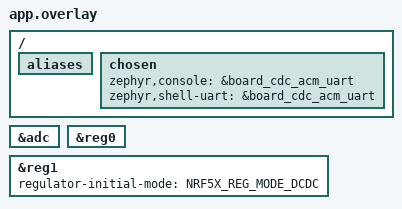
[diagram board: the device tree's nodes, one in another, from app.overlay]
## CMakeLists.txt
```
cmake_minimum_required(VERSION 3.20.0)
find_package(Zephyr REQUIRED HINTS $ENV{ZEPHYR_BASE})

project(firmware)

target_sources(app PRIVATE
    src/main.c
    src/led.c
    src/ble.c
    src/ble_service.c
    src/usb_console.c
    src/temperature.c
    src/console_commands.c
    src/dfu.c
    src/motor.c
    src/sensor.c
)
```

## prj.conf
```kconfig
CONFIG_BT=y
CONFIG_BT_PERIPHERAL=y
CONFIG_BT_DEVICE_NAME="ProMicro_BLE"
CONFIG_BT_DEVICE_APPEARANCE=833
CONFIG_BT_L2CAP_TX_MTU=498
CONFIG_BT_BUF_ACL_RX_SIZE=502
CONFIG_BT_BUF_ACL_TX_SIZE=502
CONFIG_BT_CTLR_DATA_LENGTH_MAX=251

CONFIG_GPIO=y
CONFIG_ADC=y

# USB CDC ACM console / shell
CONFIG_USB_DEVICE_STACK=y
CONFIG_USB_CDC_ACM=y
CONFIG_USB_DEVICE_INITIALIZE_AT_BOOT=n
CONFIG_USB_DEVICE_VID=0x2FE3
CONFIG_USB_DEVICE_PID=0x0100
CONFIG_SERIAL=y
CONFIG_CONSOLE=y
CONFIG_UART_CONSOLE=y
CONFIG_UART_LINE_CTRL=y
CONFIG_UART_INTERRUPT_DRIVEN=y

# Shell
CONFIG_SHELL=y
CONFIG_SHELL_BACKEND_SERIAL=y
CONFIG_SHELL_LOG_BACKEND=n
CONFIG_SHELL_PROMPT_UART="yayo:~$ "
CONFIG_MCUMGR_TRANSPORT_SHELL=y

# MCUboot / MCUmgr
CONFIG_BOOTLOADER_MCUBOOT=y
CONFIG_IMG_MANAGER=y
CONFIG_MCUMGR=y
CONFIG_MCUMGR_GRP_IMG=y
CONFIG_MCUMGR_GRP_OS=y
CONFIG_MCUMGR_GRP_OS_MCUMGR_PARAMS=y
CONFIG_MCUMGR_TRANSPORT_BT=y
CONFIG_MCUMGR_TRANSPORT_BT_CONN_PARAM_CONTROL=y
CONFIG_MCUMGR_TRANSPORT_BT_PERM_RW=y
CONFIG_MCUMGR_TRANSPORT_BT_REASSEMBLY=y
CONFIG_MCUMGR_TRANSPORT_NETBUF_SIZE=2475
CONFIG_MCUMGR_TRANSPORT_WORKQUEUE_STACK_SIZE=4608
CONFIG_NET_BUF=y
CONFIG_ZCBOR=y
CONFIG_CRC=y
CONFIG_STREAM_FLASH=y
CONFIG_BASE64=y
CONFIG_SYSTEM_WORKQUEUE_STACK_SIZE=4608
CONFIG_MAIN_STACK_SIZE=3072

# Reboot (DFU)
CONFIG_REBOOT=y

# Flash storage
CONFIG_FLASH=y
CONFIG_FLASH_MAP=y
CONFIG_NVS=y

# Temperature Sensor
CONFIG_SENSOR=y
CONFIG_TEMP_NRF5=y
```

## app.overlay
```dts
#include <zephyr/dt-bindings/pinctrl/nrf-pinctrl.h>

/ {
    aliases {
    };

    chosen {
        zephyr,console = &board_cdc_acm_uart;
        zephyr,shell-uart = &board_cdc_acm_uart;
    };
};

&adc {
    status = "okay";
};

&reg0 {
    status = "okay";
};

&reg1 {
    regulator-initial-mode = <NRF5X_REG_MODE_DCDC>;
};
```

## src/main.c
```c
#include <zephyr/kernel.h>
#include <zephyr/dfu/mcuboot.h>
#include <zephyr/sys/printk.h>

#include "usb_console.h"
#include "led.h"
#include "ble.h"
#include "temperature.h"
#include "motor.h"
#include "sensor.h"

static void confirm_running_image(void)
{
	if (boot_is_img_confirmed()) {
		return;
	}

	int err = boot_write_img_confirmed();

	if (err) {
		printk("Failed to confirm MCUboot image (err %d)\n", err);
	} else {
		printk("MCUboot image confirmed\n");
	}
}

int main(void)
{
	usb_console_init();
	confirm_running_image();

	printk("\n=== Zephyr BLE Peripheral Starting ===\n");

	if (led_init() < 0) {
		return 0;
	}

	if (ble_init() < 0) {
		return 0;
	}

	if (temperature_init() < 0) {
		return 0;
	}

	sensor_init();

	int32_t hall1 = 0, hall2 = 0;
	struct sensor_battery_status battery = { 0 };
	int battery_notify_divider = 0;

	while (1) {
		temperature_read();
		sensor_read_hall(&hall1, &hall2);
		sensor_calibration_update(hall1, hall2);
		if (sensor_should_trigger_left_click(hall1)) {
			mouse_left_click();
		}
		if (sensor_should_trigger_right_click(hall2)) {
			mouse_right_click();
		}
		mouse_switch_process();
		ble_notify_hall_sensors(hall1, hall2);
		if (++battery_notify_divider >= 20) {
			battery_notify_divider = 0;
			sensor_read_battery(&battery);
			ble_notify_battery(&battery);
		}

		k_sleep(K_MSEC(50)); // Read sensors every 50ms for smooth UI updates
	}
	return 0;
}
```

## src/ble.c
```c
#include "ble.h"

#include "ble_service.h"

#include <zephyr/bluetooth/bluetooth.h>
#include <zephyr/bluetooth/conn.h>
#include <zephyr/bluetooth/uuid.h>
#include <zephyr/kernel.h>
#include <zephyr/sys/printk.h>

/* Custom Service UUID: 2cfd0a83-f013-4fe2-8dbd-fe3a5f4a64ff */
#define BT_UUID_CUSTOM_SERV_VAL \
    BT_UUID_128_ENCODE(0x2cfd0a83, 0xf013, 0x4fe2, 0x8dbd, 0xfe3a5f4a64ff)

#define DEVICE_NAME CONFIG_BT_DEVICE_NAME
#define DEVICE_NAME_LEN (sizeof(DEVICE_NAME) - 1)

static const struct bt_data ad[] = {
    BT_DATA_BYTES(BT_DATA_FLAGS, (BT_LE_AD_GENERAL | BT_LE_AD_NO_BREDR)),
    BT_DATA_BYTES(BT_DATA_UUID16_ALL, BT_UUID_16_ENCODE(BT_UUID_GATT_VAL)),
    BT_DATA_BYTES(BT_DATA_UUID128_ALL, BT_UUID_CUSTOM_SERV_VAL),
};

static const struct bt_data sd[] = {
    BT_DATA(BT_DATA_NAME_COMPLETE, DEVICE_NAME, DEVICE_NAME_LEN),
};

static struct k_work adv_work;

static void start_advertising(void)
{
    struct bt_le_adv_param adv_param = {
        .id = BT_ID_DEFAULT,
        .sid = 0,
        .secondary_max_skip = 0,
        .options = BT_LE_ADV_OPT_CONN,
        .interval_min = 1600,
        .interval_max = 1632,
        .peer = NULL,
    };

    int err = bt_le_adv_start(&adv_param, ad, ARRAY_SIZE(ad), sd, ARRAY_SIZE(sd));

    if (err) {
        printk("Advertising failed to start (err %d)\n", err);
    } else {
        printk("Advertising successfully started\n");
    }
}

static void adv_work_handler(struct k_work *work)
{
    ARG_UNUSED(work);
    start_advertising();
}

static void connected(struct bt_conn *conn, uint8_t err)
{
    ARG_UNUSED(conn);

    if (err) {
        printk("Connection failed (err 0x%02x)\n", err);
    } else {
        printk("Connected\n");
    }
}

static void disconnected(struct bt_conn *conn, uint8_t reason)
{
    ARG_UNUSED(conn);
    printk("Disconnected (reason 0x%02x)\n", reason);
    k_work_submit(&adv_work);
}

BT_CONN_CB_DEFINE(conn_callbacks) = {
    .connected = connected,
    .disconnected = disconnected,
};

static void bt_ready(int err)
{
    if (err) {
        printk("Bluetooth init failed (err %d)\n", err);
        return;
    }

    printk("Bluetooth initialized\n");
    start_advertising();
}

int ble_notify_hall_sensors(int32_t hall1, int32_t hall2)
{
    return ble_service_notify_hall_sensors(hall1, hall2);
}

int ble_notify_battery(const struct sensor_battery_status *status)
{
    return ble_service_notify_battery(status);
}

int ble_notify_temperature(int32_t temperature)
{
    return ble_service_notify_temperature(temperature);
}

int ble_init(void)
{
    k_work_init(&adv_work, adv_work_handler);

    int err = bt_enable(bt_ready);
    if (err) {
        printk("Bluetooth init failed (err %d)\n", err);
        return err;
    }

    return 0;
}
```

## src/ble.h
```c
#ifndef BLE_H
#define BLE_H

#include <stdint.h>

struct sensor_battery_status;

int ble_init(void);
int ble_notify_temperature(int32_t temperature);
int ble_notify_hall_sensors(int32_t hall1, int32_t hall2);
int ble_notify_battery(const struct sensor_battery_status *status);

#endif
```

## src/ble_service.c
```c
#include "ble_service.h"

#include "dfu.h"
#include "led.h"
#include "motor.h"
#include "sensor.h"

#include <stdbool.h>
#include <zephyr/bluetooth/conn.h>
#include <zephyr/bluetooth/gatt.h>
#include <zephyr/bluetooth/uuid.h>
#include <zephyr/kernel.h>
#include <zephyr/sys/printk.h>

/* Custom Service UUID: 2cfd0a83-f013-4fe2-8dbd-fe3a5f4a64ff */
#define BT_UUID_CUSTOM_SERV_VAL \
    BT_UUID_128_ENCODE(0x2cfd0a83, 0xf013, 0x4fe2, 0x8dbd, 0xfe3a5f4a64ff)
#define BT_UUID_CUSTOM_SERV BT_UUID_DECLARE_128(BT_UUID_CUSTOM_SERV_VAL)

/* Custom Characteristic UUID: 2cfd0a84-f013-4fe2-8dbd-fe3a5f4a64ff */
#define BT_UUID_CUSTOM_CHAR_LED_VAL \
    BT_UUID_128_ENCODE(0x2cfd0a84, 0xf013, 0x4fe2, 0x8dbd, 0xfe3a5f4a64ff)
#define BT_UUID_CUSTOM_CHAR_LED BT_UUID_DECLARE_128(BT_UUID_CUSTOM_CHAR_LED_VAL)

/* Custom Characteristic UUID for Temp: 2cfd0a85-f013-4fe2-8dbd-fe3a5f4a64ff */
#define BT_UUID_CUSTOM_CHAR_TEMP_VAL \
    BT_UUID_128_ENCODE(0x2cfd0a85, 0xf013, 0x4fe2, 0x8dbd, 0xfe3a5f4a64ff)
#define BT_UUID_CUSTOM_CHAR_TEMP BT_UUID_DECLARE_128(BT_UUID_CUSTOM_CHAR_TEMP_VAL)

/* Custom Characteristic UUID for Battery: 2cfd0a8d-f013-4fe2-8dbd-fe3a5f4a64ff */
#define BT_UUID_CUSTOM_CHAR_BATTERY_VAL \
    BT_UUID_128_ENCODE(0x2cfd0a8d, 0xf013, 0x4fe2, 0x8dbd, 0xfe3a5f4a64ff)
#define BT_UUID_CUSTOM_CHAR_BATTERY BT_UUID_DECLARE_128(BT_UUID_CUSTOM_CHAR_BATTERY_VAL)

/* Custom Characteristic UUID for Hall1: 2cfd0a87-f013-4fe2-8dbd-fe3a5f4a64ff */
#define BT_UUID_CUSTOM_CHAR_HALL1_VAL \
    BT_UUID_128_ENCODE(0x2cfd0a87, 0xf013, 0x4fe2, 0x8dbd, 0xfe3a5f4a64ff)
#define BT_UUID_CUSTOM_CHAR_HALL1 BT_UUID_DECLARE_128(BT_UUID_CUSTOM_CHAR_HALL1_VAL)

/* Custom Characteristic UUID for Hall2: 2cfd0a88-f013-4fe2-8dbd-fe3a5f4a64ff */
#define BT_UUID_CUSTOM_CHAR_HALL2_VAL \
    BT_UUID_128_ENCODE(0x2cfd0a88, 0xf013, 0x4fe2, 0x8dbd, 0xfe3a5f4a64ff)
#define BT_UUID_CUSTOM_CHAR_HALL2 BT_UUID_DECLARE_128(BT_UUID_CUSTOM_CHAR_HALL2_VAL)

/* Custom Characteristic UUID for Mouse Switch: 2cfd0a89-f013-4fe2-8dbd-fe3a5f4a64ff */
#define BT_UUID_CUSTOM_CHAR_SWITCH_VAL \
    BT_UUID_128_ENCODE(0x2cfd0a89, 0xf013, 0x4fe2, 0x8dbd, 0xfe3a5f4a64ff)
#define BT_UUID_CUSTOM_CHAR_SWITCH BT_UUID_DECLARE_128(BT_UUID_CUSTOM_CHAR_SWITCH_VAL)

/* Custom Characteristic UUID for Calibration Status: 2cfd0a8a-f013-4fe2-8dbd-fe3a5f4a64ff */
#define BT_UUID_CUSTOM_CHAR_CAL_STATUS_VAL \
    BT_UUID_128_ENCODE(0x2cfd0a8a, 0xf013, 0x4fe2, 0x8dbd, 0xfe3a5f4a64ff)
#define BT_UUID_CUSTOM_CHAR_CAL_STATUS BT_UUID_DECLARE_128(BT_UUID_CUSTOM_CHAR_CAL_STATUS_VAL)

/* Custom Characteristic UUID for Calibration Command: 2cfd0a8b-f013-4fe2-8dbd-fe3a5f4a64ff */
#define BT_UUID_CUSTOM_CHAR_CAL_COMMAND_VAL \
    BT_UUID_128_ENCODE(0x2cfd0a8b, 0xf013, 0x4fe2, 0x8dbd, 0xfe3a5f4a64ff)
#define BT_UUID_CUSTOM_CHAR_CAL_COMMAND BT_UUID_DECLARE_128(BT_UUID_CUSTOM_CHAR_CAL_COMMAND_VAL)

/* Custom Characteristic UUID for System Control: 2cfd0a8c-f013-4fe2-8dbd-fe3a5f4a64ff */
#define BT_UUID_CUSTOM_CHAR_SYSTEM_CONTROL_VAL \
    BT_UUID_128_ENCODE(0x2cfd0a8c, 0xf013, 0x4fe2, 0x8dbd, 0xfe3a5f4a64ff)
#define BT_UUID_CUSTOM_CHAR_SYSTEM_CONTROL BT_UUID_DECLARE_128(BT_UUID_CUSTOM_CHAR_SYSTEM_CONTROL_VAL)

enum {
    TEMP_NOTIFY_ATTR_INDEX = 4,
    BATTERY_NOTIFY_ATTR_INDEX = 7,
    HALL1_NOTIFY_ATTR_INDEX = 9,
    HALL2_NOTIFY_ATTR_INDEX = 12,
};

enum system_control_command {
    SYSTEM_CONTROL_CMD_REBOOT = 1,
    SYSTEM_CONTROL_CMD_DFU = 2,
    SYSTEM_CONTROL_CMD_OTA = 3,
};

static bool temp_notify_enabled;
static bool battery_notify_enabled;
static bool hall1_notify_enabled;
static bool hall2_notify_enabled;
static uint8_t pending_system_command;

struct __packed ble_battery_payload {
    uint16_t millivolts;
    uint8_t percent;
};

static void system_control_work_handler(struct k_work *work);
K_WORK_DELAYABLE_DEFINE(system_control_work, system_control_work_handler);

static void temp_ccc_cfg_changed(const struct bt_gatt_attr *attr, uint16_t value)
{
    ARG_UNUSED(attr);
    temp_notify_enabled = (value == BT_GATT_CCC_NOTIFY);
    printk("Temperature notifications %s\n",
           temp_notify_enabled ? "enabled" : "disabled");
}

static void hall1_ccc_cfg_changed(const struct bt_gatt_attr *attr, uint16_t value)
{
    ARG_UNUSED(attr);
    hall1_notify_enabled = (value == BT_GATT_CCC_NOTIFY);
}

static void battery_ccc_cfg_changed(const struct bt_gatt_attr *attr, uint16_t value)
{
    ARG_UNUSED(attr);
    battery_notify_enabled = (value == BT_GATT_CCC_NOTIFY);
}

static void hall2_ccc_cfg_changed(const struct bt_gatt_attr *attr, uint16_t value)
{
    ARG_UNUSED(attr);
    hall2_notify_enabled = (value == BT_GATT_CCC_NOTIFY);
}

static void system_control_work_handler(struct k_work *work)
{
    ARG_UNUSED(work);

    switch (pending_system_command) {
    case SYSTEM_CONTROL_CMD_REBOOT:
        printk("System control: reboot\n");
        dfu_reboot();
        break;
    case SYSTEM_CONTROL_CMD_DFU:
        printk("System control: reboot through MCUboot\n");
        dfu_reboot_to_bootloader();
        break;
    case SYSTEM_CONTROL_CMD_OTA:
        printk("System control: test uploaded image and reboot\n");
        dfu_reboot_to_ota();
        break;
    default:
        break;
    }
}

static ssize_t write_led(struct bt_conn *conn, const struct bt_gatt_attr *attr,
                         const void *buf, uint16_t len, uint16_t offset, uint8_t flags)
{
    ARG_UNUSED(conn);
    ARG_UNUSED(attr);
    ARG_UNUSED(offset);
    ARG_UNUSED(flags);

    const uint8_t *value = buf;

    if (len >= 1U) {
        if (value[0] == 1U || value[0] == '1') {
            led_set(true);
            printk("LED command received: ON\n");
        } else if (value[0] == 0U || value[0] == '0') {
            led_set(false);
            printk("LED command received: OFF\n");
        }
    }

    return len;
}

static ssize_t read_led(struct bt_conn *conn, const struct bt_gatt_attr *attr,
                        void *buf, uint16_t len, uint16_t offset)
{
    uint8_t value = led_get() ? 1U : 0U;
    return bt_gatt_attr_read(conn, attr, buf, len, offset, &value, sizeof(value));
}

static ssize_t write_switch(struct bt_conn *conn, const struct bt_gatt_attr *attr,
                            const void *buf, uint16_t len, uint16_t offset, uint8_t flags)
{
    ARG_UNUSED(conn);
    ARG_UNUSED(attr);
    ARG_UNUSED(offset);
    ARG_UNUSED(flags);

    const uint8_t *value = buf;

    if (len >= 1U) {
        mouse_right_switch_set(value[0] == 1U);
    }

    return len;
}

static ssize_t read_calibration_status(struct bt_conn *conn, const struct bt_gatt_attr *attr,
                                       void *buf, uint16_t len, uint16_t offset)
{
    struct sensor_calibration_status status;

    ARG_UNUSED(attr);
    sensor_get_calibration_status(&status);

    return bt_gatt_attr_read(conn, attr, buf, len, offset, &status, sizeof(status));
}

static ssize_t read_battery_status(struct bt_conn *conn, const struct bt_gatt_attr *attr,
                                   void *buf, uint16_t len, uint16_t offset)
{
    struct sensor_battery_status status;
    struct ble_battery_payload payload;

    ARG_UNUSED(attr);

    sensor_read_battery(&status);
    payload.millivolts = status.millivolts;
    payload.percent = status.percent;

    return bt_gatt_attr_read(conn, attr, buf, len, offset, &payload, sizeof(payload));
}

static ssize_t write_calibration_command(struct bt_conn *conn, const struct bt_gatt_attr *attr,
                                         const void *buf, uint16_t len, uint16_t offset,
                                         uint8_t flags)
{
    ARG_UNUSED(conn);
    ARG_UNUSED(attr);
    ARG_UNUSED(offset);
    ARG_UNUSED(flags);

    const uint8_t *value = buf;

    if ((len < 1U) || (sensor_start_calibration(value[0]) != 0)) {
        return BT_GATT_ERR(BT_ATT_ERR_VALUE_NOT_ALLOWED);
    }

    printk("Calibration command: %u\n", value[0]);
    return len;
}

static ssize_t write_system_control(struct bt_conn *conn, const struct bt_gatt_attr *attr,
                                    const void *buf, uint16_t len, uint16_t offset,
                                    uint8_t flags)
{
    ARG_UNUSED(conn);
    ARG_UNUSED(attr);
    ARG_UNUSED(offset);
    ARG_UNUSED(flags);

    const uint8_t *value = buf;

    if (len < 1U) {
        return BT_GATT_ERR(BT_ATT_ERR_INVALID_ATTRIBUTE_LEN);
    }

    switch (value[0]) {
    case SYSTEM_CONTROL_CMD_REBOOT:
    case SYSTEM_CONTROL_CMD_DFU:
    case SYSTEM_CONTROL_CMD_OTA:
        pending_system_command = value[0];
        k_work_schedule(&system_control_work, K_MSEC(100));
        return len;
    default:
        return BT_GATT_ERR(BT_ATT_ERR_VALUE_NOT_ALLOWED);
    }
}

BT_GATT_SERVICE_DEFINE(custom_srv,
    BT_GATT_PRIMARY_SERVICE(BT_UUID_CUSTOM_SERV),
    BT_GATT_CHARACTERISTIC(BT_UUID_CUSTOM_CHAR_LED,
                           BT_GATT_CHRC_READ | BT_GATT_CHRC_WRITE,
                           BT_GATT_PERM_READ | BT_GATT_PERM_WRITE,
                           read_led, write_led, NULL),
    BT_GATT_CHARACTERISTIC(BT_UUID_CUSTOM_CHAR_TEMP,
                           BT_GATT_CHRC_NOTIFY,
                           BT_GATT_PERM_NONE,
                           NULL, NULL, NULL),
    BT_GATT_CCC(temp_ccc_cfg_changed,
                BT_GATT_PERM_READ | BT_GATT_PERM_WRITE),
    BT_GATT_CHARACTERISTIC(BT_UUID_CUSTOM_CHAR_BATTERY,
                           BT_GATT_CHRC_READ | BT_GATT_CHRC_NOTIFY,
                           BT_GATT_PERM_READ,
                           read_battery_status, NULL, NULL),
    BT_GATT_CCC(battery_ccc_cfg_changed,
                BT_GATT_PERM_READ | BT_GATT_PERM_WRITE),
    BT_GATT_CHARACTERISTIC(BT_UUID_CUSTOM_CHAR_HALL1,
                           BT_GATT_CHRC_NOTIFY,
                           BT_GATT_PERM_NONE,
                           NULL, NULL, NULL),
    BT_GATT_CCC(hall1_ccc_cfg_changed,
                BT_GATT_PERM_READ | BT_GATT_PERM_WRITE),
    BT_GATT_CHARACTERISTIC(BT_UUID_CUSTOM_CHAR_HALL2,
                           BT_GATT_CHRC_NOTIFY,
                           BT_GATT_PERM_NONE,
                           NULL, NULL, NULL),
    BT_GATT_CCC(hall2_ccc_cfg_changed,
                BT_GATT_PERM_READ | BT_GATT_PERM_WRITE),
    BT_GATT_CHARACTERISTIC(BT_UUID_CUSTOM_CHAR_SWITCH,
                           BT_GATT_CHRC_WRITE,
                           BT_GATT_PERM_WRITE,
                           NULL, write_switch, NULL),
    BT_GATT_CHARACTERISTIC(BT_UUID_CUSTOM_CHAR_CAL_STATUS,
                           BT_GATT_CHRC_READ,
                           BT_GATT_PERM_READ,
                           read_calibration_status, NULL, NULL),
    BT_GATT_CHARACTERISTIC(BT_UUID_CUSTOM_CHAR_CAL_COMMAND,
                           BT_GATT_CHRC_WRITE,
                           BT_GATT_PERM_WRITE,
                           NULL, write_calibration_command, NULL),
    BT_GATT_CHARACTERISTIC(BT_UUID_CUSTOM_CHAR_SYSTEM_CONTROL,
                           BT_GATT_CHRC_WRITE,
                           BT_GATT_PERM_WRITE,
                           NULL, write_system_control, NULL),
);

int ble_service_notify_hall_sensors(int32_t hall1, int32_t hall2)
{
    int err = 0;

    if (hall1_notify_enabled) {
        err = bt_gatt_notify(NULL, &custom_srv.attrs[HALL1_NOTIFY_ATTR_INDEX],
                             &hall1, sizeof(hall1));
    }

    if (hall2_notify_enabled) {
        err = bt_gatt_notify(NULL, &custom_srv.attrs[HALL2_NOTIFY_ATTR_INDEX],
                             &hall2, sizeof(hall2));
    }

    return err;
}

int ble_service_notify_temperature(int32_t temperature)
{
    if (!temp_notify_enabled) {
        return 0;
    }

    return bt_gatt_notify(NULL, &custom_srv.attrs[TEMP_NOTIFY_ATTR_INDEX],
                          &temperature, sizeof(temperature));
}

int ble_service_notify_battery(const struct sensor_battery_status *status)
{
    struct ble_battery_payload payload;

    if (!battery_notify_enabled || !status) {
        return 0;
    }

    payload.millivolts = status->millivolts;
    payload.percent = status->percent;

    return bt_gatt_notify(NULL, &custom_srv.attrs[BATTERY_NOTIFY_ATTR_INDEX],
                          &payload, sizeof(payload));
}
```

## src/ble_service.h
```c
#ifndef BLE_SERVICE_H
#define BLE_SERVICE_H

#include <stdint.h>

struct sensor_battery_status;

int ble_service_notify_temperature(int32_t temperature);
int ble_service_notify_hall_sensors(int32_t hall1, int32_t hall2);
int ble_service_notify_battery(const struct sensor_battery_status *status);

#endif
```

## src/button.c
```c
#include "button.h"

#include "dfu.h"

#include <inttypes.h>
#include <zephyr/device.h>
#include <zephyr/drivers/gpio.h>
#include <zephyr/kernel.h>
#include <zephyr/sys/printk.h>

#define SW0_NODE DT_ALIAS(sw0)
#if !DT_NODE_HAS_STATUS(SW0_NODE, okay)
#error "Unsupported board: sw0 devicetree alias is not defined"
#endif

static const struct gpio_dt_spec button = GPIO_DT_SPEC_GET_OR(SW0_NODE, gpios, {0});
static struct gpio_callback button_cb_data;

static void button_pressed(const struct device *dev, struct gpio_callback *cb,
                           uint32_t pins)
{
    ARG_UNUSED(dev);
    ARG_UNUSED(cb);
    ARG_UNUSED(pins);

    printk("Button pressed at %" PRIu32 "\n", k_cycle_get_32());
    printk("Rebooting through MCUboot...\n");
    dfu_reboot_to_bootloader();
}

int button_init(void)
{
    int ret;

    if (!gpio_is_ready_dt(&button)) {
        printk("Error: button device %s is not ready\n", button.port->name);
        return -1;
    }

    ret = gpio_pin_configure_dt(&button, GPIO_INPUT | GPIO_PULL_UP);
    if (ret != 0) {
        printk("Error %d: failed to configure %s pin %d\n",
               ret, button.port->name, button.pin);
        return -1;
    }

    ret = gpio_pin_interrupt_configure_dt(&button, GPIO_INT_EDGE_TO_ACTIVE);
    if (ret != 0) {
        printk("Error %d: failed to configure interrupt on %s pin %d\n",
               ret, button.port->name, button.pin);
        return -1;
    }

    gpio_init_callback(&button_cb_data, button_pressed, BIT(button.pin));
    gpio_add_callback(button.port, &button_cb_data);
    printk("Set up button at %s pin %d\n", button.port->name, button.pin);

    return 0;
}
```

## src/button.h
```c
#ifndef BUTTON_H
#define BUTTON_H

int button_init(void);

#endif
```

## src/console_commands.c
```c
#include <zephyr/shell/shell.h>

#include "dfu.h"

static int cmd_reboot(const struct shell *sh, size_t argc, char **argv)
{
    ARG_UNUSED(argc);
    ARG_UNUSED(argv);

    shell_print(sh, "Rebooting...");
    dfu_reboot();
    return 0;
}

static int cmd_dfu(const struct shell *sh, size_t argc, char **argv)
{
    ARG_UNUSED(argc);
    ARG_UNUSED(argv);

    shell_print(sh, "Rebooting. MCUboot will run before returning to the application.");
    dfu_reboot_to_bootloader();
    return 0;
}

static int cmd_ota(const struct shell *sh, size_t argc, char **argv)
{
    ARG_UNUSED(argc);
    ARG_UNUSED(argv);

    shell_print(sh, "Marking the uploaded image for test boot and rebooting...");
    dfu_reboot_to_ota();
    return 0;
}

SHELL_CMD_REGISTER(reboot, NULL, "Reboot the device", cmd_reboot);
SHELL_CMD_REGISTER(dfu, NULL, "Reboot through MCUboot", cmd_dfu);
SHELL_CMD_REGISTER(ota, NULL, "Test the uploaded MCUboot image and reboot", cmd_ota);
```

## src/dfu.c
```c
#include "dfu.h"

#include <zephyr/dfu/mcuboot.h>
#include <zephyr/sys/printk.h>
#include <zephyr/sys/reboot.h>

void dfu_reboot(void)
{
    sys_reboot(SYS_REBOOT_COLD);
}

void dfu_reboot_to_bootloader(void)
{
    sys_reboot(SYS_REBOOT_COLD);
}

void dfu_reboot_to_ota(void)
{
    int err = boot_request_upgrade(BOOT_UPGRADE_TEST);

    if (err == 0) {
        sys_reboot(SYS_REBOOT_COLD);
    } else {
        printk("Failed to request MCUboot test boot (err %d)\n", err);
    }
}
```

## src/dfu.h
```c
#ifndef DFU_H
#define DFU_H

void dfu_reboot(void);
void dfu_reboot_to_bootloader(void);
void dfu_reboot_to_ota(void);

#endif
```

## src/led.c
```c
#include "led.h"
#include <zephyr/kernel.h>
#include <zephyr/drivers/gpio.h>
#include <zephyr/sys/printk.h>

#define LED0_NODE DT_ALIAS(led0)
static const struct gpio_dt_spec led = GPIO_DT_SPEC_GET(LED0_NODE, gpios);

int led_init(void)
{
	if (!gpio_is_ready_dt(&led)) {
		printk("Error: LED device %s is not ready\n", led.port->name);
		return -1;
	}

	int err = gpio_pin_configure_dt(&led, GPIO_OUTPUT_INACTIVE);
	if (err < 0) {
		printk("Error: failed to configure led0\n");
		return err;
	}
	return 0;
}

void led_set(bool state)
{
	gpio_pin_set_dt(&led, state ? 1 : 0);
}

bool led_get(void)
{
	return gpio_pin_get_dt(&led) > 0;
}
```

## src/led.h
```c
#ifndef LED_H
#define LED_H

#include <stdbool.h>

int led_init(void);
void led_set(bool state);
bool led_get(void);

#endif
```

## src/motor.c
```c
#include "motor.h"

#include <zephyr/device.h>
#include <zephyr/drivers/gpio.h>
#include <zephyr/init.h>
#include <zephyr/kernel.h>
#include <zephyr/sys/printk.h>

#define MOUSE_SWITCH_NODE DT_NODELABEL(gpio1)
#define MOUSE_RIGHT_SWITCH_PIN 11
#define MOUSE_LEFT_SWITCH_PIN 13

static const struct device *gpio1_dev;
static int64_t left_click_release_at;
static int64_t right_click_release_at;

void mouse_left_switch_set(bool state)
{
    if (!gpio1_dev || !device_is_ready(gpio1_dev)) {
        return;
    }

    gpio_pin_set(gpio1_dev, MOUSE_LEFT_SWITCH_PIN, state ? 1 : 0);
    printk("Mouse left switch (P1.13) %s\n", state ? "ON" : "OFF");
}

void mouse_right_switch_set(bool state)
{
    if (!gpio1_dev || !device_is_ready(gpio1_dev)) {
        return;
    }

    gpio_pin_set(gpio1_dev, MOUSE_RIGHT_SWITCH_PIN, state ? 1 : 0);
    printk("Mouse right switch (P1.11) %s\n", state ? "ON" : "OFF");
}

void mouse_left_click(void)
{
    mouse_left_switch_set(true);
    left_click_release_at = k_uptime_get() + 20;
}

void mouse_right_click(void)
{
    mouse_right_switch_set(true);
    right_click_release_at = k_uptime_get() + 20;
}

void mouse_switch_process(void)
{
    if ((left_click_release_at != 0) &&
        (k_uptime_get() >= left_click_release_at)) {
        mouse_left_switch_set(false);
        left_click_release_at = 0;
    }

    if ((right_click_release_at != 0) &&
        (k_uptime_get() >= right_click_release_at)) {
        mouse_right_switch_set(false);
        right_click_release_at = 0;
    }
}

static int mouse_switch_init(void)
{
    gpio1_dev = DEVICE_DT_GET(MOUSE_SWITCH_NODE);
    if (!device_is_ready(gpio1_dev)) {
        printk("GPIO device (gpio1) not ready!\n");
        return -1;
    }

    gpio_pin_configure(gpio1_dev, MOUSE_RIGHT_SWITCH_PIN, GPIO_OUTPUT_INACTIVE);
    gpio_pin_configure(gpio1_dev, MOUSE_LEFT_SWITCH_PIN, GPIO_OUTPUT_INACTIVE);
    printk("Mouse switches initialized on P1.11(right), P1.13(left)\n");
    return 0;
}

SYS_INIT(mouse_switch_init, APPLICATION, 0);
```
